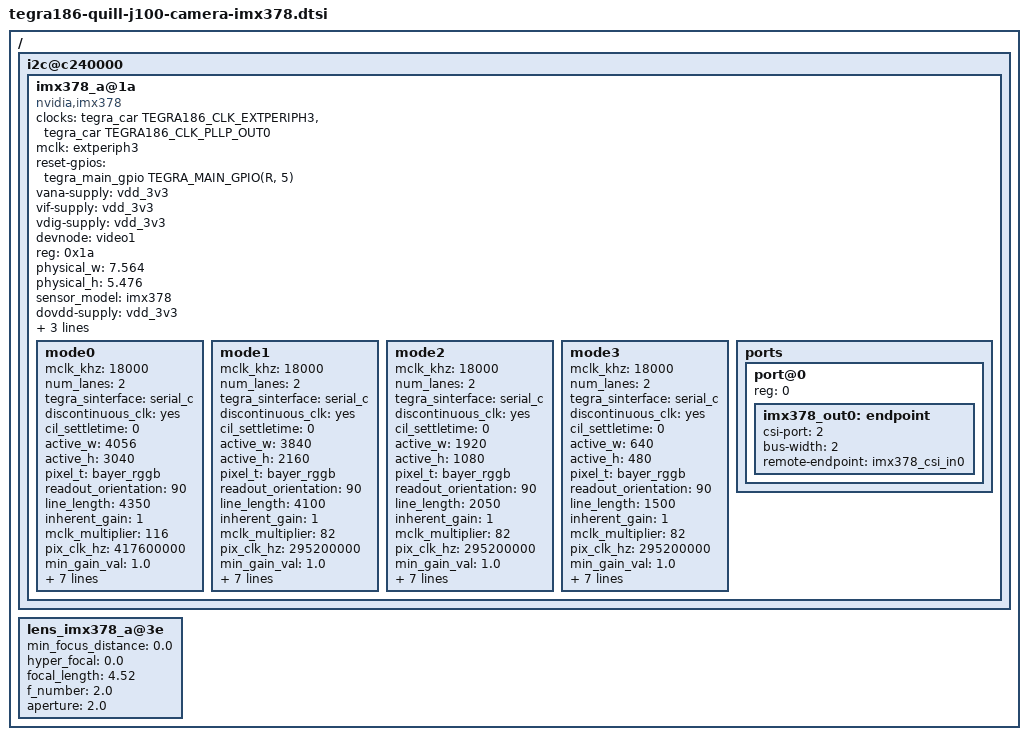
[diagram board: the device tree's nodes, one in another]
/ {
	i2c@c240000 {
		imx378_a@1a {
			/* Define any required hw resources needed by driver */
			/* ie. clocks, io pins, power sources */
			clocks = <&tegra_car TEGRA186_CLK_EXTPERIPH3>,
					 <&tegra_car TEGRA186_CLK_PLLP_OUT0>;
			clock-names = "extperiph3", "pllp_grtba";
			mclk = "extperiph3";
			reset-gpios = <&tegra_main_gpio TEGRA_MAIN_GPIO(R, 5) GPIO_ACTIVE_HIGH>;
			vana-supply = <&vdd_3v3>;
			vif-supply = <&vdd_3v3>;
			vdig-supply = <&vdd_3v3>;
			status = "okay";
			
			devnode = "video1";
			compatible = "nvidia,imx378";
			reg = <0x1a>;

			physical_w = "7.564";
			physical_h = "5.476";

			sensor_model ="imx378";
			dovdd-supply = <&vdd_3v3>;
			avdd-reg = "vana";
			dvdd-reg = "vdig";
			iovdd-reg = "dovdd";

			mode0 { // IMX378_MODE_4056X3040
				mclk_khz = "18000";
				num_lanes = "2";
				tegra_sinterface = "serial_c";
				discontinuous_clk = "yes";
				cil_settletime = "0";
				active_w = "4056";
				active_h = "3040";
				pixel_t = "bayer_rggb";
				readout_orientation = "90";
				line_length = "4350";
				inherent_gain = "1";
				mclk_multiplier = "116";
				pix_clk_hz = "417600000";

				min_gain_val = "1.0";
				max_gain_val = "22.0";
				min_hdr_ratio = "1";
				max_hdr_ratio = "64";
				min_framerate = "1";
				max_framerate = "30";
				min_exp_time = "1";
				max_exp_time = "65515";
			};
			mode1 { // IMX378_MODE_3840X2160
				mclk_khz = "18000";
				num_lanes = "2";
				tegra_sinterface = "serial_c";
				discontinuous_clk = "yes";
				cil_settletime = "0";
				active_w = "3840";
				active_h = "2160";
				pixel_t = "bayer_rggb";
				readout_orientation = "90";
				line_length = "4100";
				inherent_gain = "1";
				mclk_multiplier = "82";
				pix_clk_hz = "295200000";

				min_gain_val = "1.0";
				max_gain_val = "22.0";
				min_hdr_ratio = "1";
				max_hdr_ratio = "64";
				min_framerate = "1";
				max_framerate = "30";
				min_exp_time = "1";
				max_exp_time = "65515";
			};
			mode2 { // IMX378_MODE_1920X1080
				mclk_khz = "18000";
				num_lanes = "2";
				tegra_sinterface = "serial_c";
				discontinuous_clk = "yes";
				cil_settletime = "0";
				active_w = "1920";
				active_h = "1080";
				pixel_t = "bayer_rggb";
				readout_orientation = "90";
				line_length = "2050";
				inherent_gain = "1";
				mclk_multiplier = "82";
				pix_clk_hz = "295200000";

				min_gain_val = "1.0";
				max_gain_val = "22.0";
				min_hdr_ratio = "1";
				max_hdr_ratio = "64";
				min_framerate = "1";
				max_framerate = "120";
				min_exp_time = "1";
				max_exp_time = "65515";
			};
			mode3 { // IMX378_MODE_640X480
				mclk_khz = "18000";
				num_lanes = "2";
				tegra_sinterface = "serial_c";
				discontinuous_clk = "yes";
				cil_settletime = "0";
				active_w = "640";
				active_h = "480";
				pixel_t = "bayer_rggb";
				readout_orientation = "90";
				line_length = "1500";
				inherent_gain = "1";
				mclk_multiplier = "82";
				pix_clk_hz = "295200000";

				min_gain_val = "1.0";
				max_gain_val = "22.0";
				min_hdr_ratio = "1";
				max_hdr_ratio = "64";
				min_framerate = "1";
				max_framerate = "240";
				min_exp_time = "1";
				max_exp_time = "65515";
			};
			ports {
				#address-cells = <1>;
				#size-cells = <0>;
				port@0 {
					reg = <0>;
					imx378_out0: endpoint {
						csi-port = <2>;
						bus-width = <2>;
						remote-endpoint = <&imx378_csi_in0>;
					};
				};
			};
		};
	};

	lens_imx378_a@3e {
		min_focus_distance = "0.0";
		hyper_focal = "0.0";
		focal_length = "4.52";
		f_number = "2.0";
		aperture = "2.0";
	};
};
